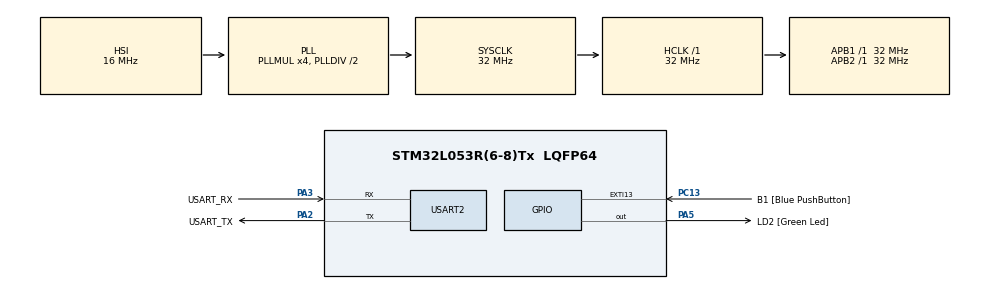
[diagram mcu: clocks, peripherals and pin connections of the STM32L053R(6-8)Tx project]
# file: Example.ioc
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Mcu.Family=STM32L0
Mcu.Name=STM32L053R(6-8)Tx
Mcu.Package=LQFP64
PA13.GPIO_Label=TMS
PA13.Mode=Serial_Wire
PA13.Signal=SYS_SWDIO
PA14.GPIO_Label=TCK
PA14.Mode=Serial_Wire
PA14.Signal=SYS_SWCLK
PA2.GPIO_Label=USART_TX
PA2.Mode=Asynchronous
PA2.Signal=USART2_TX
PA3.GPIO_Label=USART_RX
PA3.Mode=Asynchronous
PA3.Signal=USART2_RX
PA5.GPIO_Label=LD2 [Green Led]
PA5.Signal=GPIO_Output
PC13.GPIO_Label=B1 [Blue PushButton]
PC13.GPIO_ModeDefaultEXTI=GPIO_MODE_IT_FALLING
PC13.Signal=GPXTI13
PC14-OSC32_IN.Mode=LSE-External-Oscillator
PC14-OSC32_IN.Signal=RCC_OSC32_IN
PC15-OSC32_OUT.Mode=LSE-External-Oscillator
PC15-OSC32_OUT.Signal=RCC_OSC32_OUT
PH0-OSC_IN.Mode=HSE-External-Clock-Source
PH0-OSC_IN.Signal=RCC_OSC_IN
PH1-OSC_OUT.Signal=RCC_OSC_OUT
ProjectManager.HeapSize=0x200
ProjectManager.StackSize=0x400
ProjectManager.TargetToolchain=MDK-ARM V5.27
RCC.AHBFreq_Value=32000000
RCC.APB1Freq_Value=32000000
RCC.APB1TimFreq_Value=32000000
RCC.APB2Freq_Value=32000000
RCC.APB2TimFreq_Value=32000000
RCC.HCLKFreq_Value=32000000
RCC.HSE_VALUE=8000000
RCC.HSI16_VALUE=16000000
RCC.HSI48_VALUE=48000000
RCC.HSI_VALUE=16000000
RCC.MSI_VALUE=2097000
RCC.PLLMUL=RCC_PLLMUL_4
RCC.SYSCLKFreq_VALUE=32000000
RCC.SYSCLKSource=RCC_SYSCLKSOURCE_PLLCLK
RCC.VCOOutputFreq_Value=64000000
USART2.VirtualMode-Asynchronous=VM_ASYNC
board=NUCLEO-L053R8

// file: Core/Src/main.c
/* USER CODE BEGIN Header */
/**
  ******************************************************************************
  * @file           : main.c
  * @brief          : Main program body
  ******************************************************************************
  * @attention
  *
  * <h2><center>&copy; Copyright (c) 2020 STMicroelectronics.
  * All rights reserved.</center></h2>
  *
  * This software component is licensed by ST under BSD 3-Clause license,
  * the "License"; You may not use this file except in compliance with the
  * License. You may obtain a copy of the License at:
  *                        opensource.org/licenses/BSD-3-Clause
  *
  ******************************************************************************
  */
/* USER CODE END Header */
#include "main.h"
#include "usart.h"
#include "gpio.h"
#include "stm_coslib.h"

void SystemClock_Config(void);

/* USER CODE BEGIN 0 */

/* define task*/
task_t ValueInc,GlobalReset;
/* define button*/
button_t Button_1,Button_2,Button_3;
/* define menuitems */
menu_t Root,Menu1,Menu2;

uint32_t TimerInc;

/*

  B1 button is defined in c file
		button_typedef Button_Def[__COS_BUTTON_ButonTypeSize]=
		{
			{B1_GPIO_Port,B1_Pin}
		};

*/

/* USER CODE END 0 */

int main(void)
{

  /* MCU Configuration--------------------------------------------------------*/

  /* Reset of all peripherals, Initializes the Flash interface and the Systick. */
  HAL_Init();

  /* Configure the system clock */
  SystemClock_Config();
 SysTick_Config(SystemCoreClock/1000); //1ms update

  /* Initialize all configured peripherals */
  MX_GPIO_Init();
  MX_USART2_UART_Init();
  /* USER CODE BEGIN 2 */

/* Create buttons, high time - first definition order*/
COS_BUTTON_Create(&Button_3,__COS_BUTTON_GET_TYPEDEF(0),2000,Falling_Edge,IRQ_Break); //2sec, BUTTON_IRQ_FLAG.Bits.BIT_0
COS_BUTTON_Create(&Button_2,__COS_BUTTON_GET_TYPEDEF(0),1000,Falling_Edge,IRQ_Break); //1sec push time, BUTTON_IRQ_FLAG.Bits.BIT_1
COS_BUTTON_Create(&Button_1,__COS_BUTTON_GET_TYPEDEF(0),50,Falling_Edge,IRQ_Break); //50ms push time, BUTTON_IRQ_FLAG.Bits.BIT_2

/* Create tasks*/
COS_TASK_Create(&ValueInc,1000,TASK_RUN); //1 sec
COS_TASK_Create(&GlobalReset,20000,TASK_RUN); //20 sec

/*Create menus*/
COS_MENU_SetRoot(&Root);
COS_MENU_AddTo(&Root,&Menu1); //First child
COS_MENU_AddTo(&Root,&Menu2); //Sibling

COS_TASK_Scheduler();

}

/* Task control*/
void COS_TASK_TimeEllapsedCallBack(task_t *Task)
{
	if(Task==&ValueInc)
	{
	  TimerInc++;
	}
	else if(Task==&GlobalReset)
	{
		TimerInc=0;
	  COS_MENU_BackToRoot();
	}

}

/* Menu and button control*/
void COS_MENU_EventHandle(menu_t *Menu)
{

	if(Menu==&Root)
	{

		if(BUTTON_IRQ_FLAG.Bits.BIT_2)
		{
		   HAL_GPIO_TogglePin(LD2_GPIO_Port,LD2_Pin);
		}
		else if(BUTTON_IRQ_FLAG.Bits.BIT_1)
		{
      COS_MENU_MoveToChild(1);
		}
		else if(BUTTON_IRQ_FLAG.Bits.BIT_0)
		{

		}

	}
	else if(Menu==&Menu1)
	{

		if(BUTTON_IRQ_FLAG.Bits.BIT_2)
		{
       COS_MENU_Move(MENU_GOTO_FORWARD);
		}
		else if(BUTTON_IRQ_FLAG.Bits.BIT_1)
		{
       COS_MENU_Move(MENU_GOTO_BACKWARD);
		}
		else if(BUTTON_IRQ_FLAG.Bits.BIT_0)
		{
      COS_MENU_BackToRoot();
		}

	}
	else if(Menu==&Menu2)
	{

		if(BUTTON_IRQ_FLAG.Bits.BIT_2)
		{
       COS_MENU_Move(MENU_GOTO_FORWARD);
		}
		else if(BUTTON_IRQ_FLAG.Bits.BIT_1)
		{
       COS_MENU_Move(MENU_GOTO_BACKWARD);
		}
		else if(BUTTON_IRQ_FLAG.Bits.BIT_0)
		{
      COS_MENU_BackToRoot();
		}

	}

	/* if any button pushed, Reset the reset task timer*/
	if(BUTTON_IRQ_FLAG.Bulk)
	{
	  COS_TASK_RefreshTimer(&GlobalReset);
	}

}

void SystemClock_Config(void)
{
  RCC_OscInitTypeDef RCC_OscInitStruct = {0};
  RCC_ClkInitTypeDef RCC_ClkInitStruct = {0};
  RCC_PeriphCLKInitTypeDef PeriphClkInit = {0};

  /** Configure the main internal regulator output voltage
  */
  __HAL_PWR_VOLTAGESCALING_CONFIG(PWR_REGULATOR_VOLTAGE_SCALE1);
  /** Initializes the RCC Oscillators according to the specified parameters
  * in the RCC_OscInitTypeDef structure.
  */
  RCC_OscInitStruct.OscillatorType = RCC_OSCILLATORTYPE_HSI;
  RCC_OscInitStruct.HSIState = RCC_HSI_ON;
  RCC_OscInitStruct.HSICalibrationValue = RCC_HSICALIBRATION_DEFAULT;
  RCC_OscInitStruct.PLL.PLLState = RCC_PLL_ON;
  RCC_OscInitStruct.PLL.PLLSource = RCC_PLLSOURCE_HSI;
  RCC_OscInitStruct.PLL.PLLMUL = RCC_PLLMUL_4;
  RCC_OscInitStruct.PLL.PLLDIV = RCC_PLLDIV_2;
  if (HAL_RCC_OscConfig(&RCC_OscInitStruct) != HAL_OK)
  {
    Error_Handler();
  }
  /** Initializes the CPU, AHB and APB buses clocks
  */
  RCC_ClkInitStruct.ClockType = RCC_CLOCKTYPE_HCLK|RCC_CLOCKTYPE_SYSCLK
                              |RCC_CLOCKTYPE_PCLK1|RCC_CLOCKTYPE_PCLK2;
  RCC_ClkInitStruct.SYSCLKSource = RCC_SYSCLKSOURCE_PLLCLK;
  RCC_ClkInitStruct.AHBCLKDivider = RCC_SYSCLK_DIV1;
  RCC_ClkInitStruct.APB1CLKDivider = RCC_HCLK_DIV1;
  RCC_ClkInitStruct.APB2CLKDivider = RCC_HCLK_DIV1;

  if (HAL_RCC_ClockConfig(&RCC_ClkInitStruct, FLASH_LATENCY_1) != HAL_OK)
  {
    Error_Handler();
  }
  PeriphClkInit.PeriphClockSelection = RCC_PERIPHCLK_USART2;
  PeriphClkInit.Usart2ClockSelection = RCC_USART2CLKSOURCE_PCLK1;
  if (HAL_RCCEx_PeriphCLKConfig(&PeriphClkInit) != HAL_OK)
  {
    Error_Handler();
  }
}

void Error_Handler(void)
{
}

/************************ (C) COPYRIGHT STMicroelectronics *****END OF FILE****/
